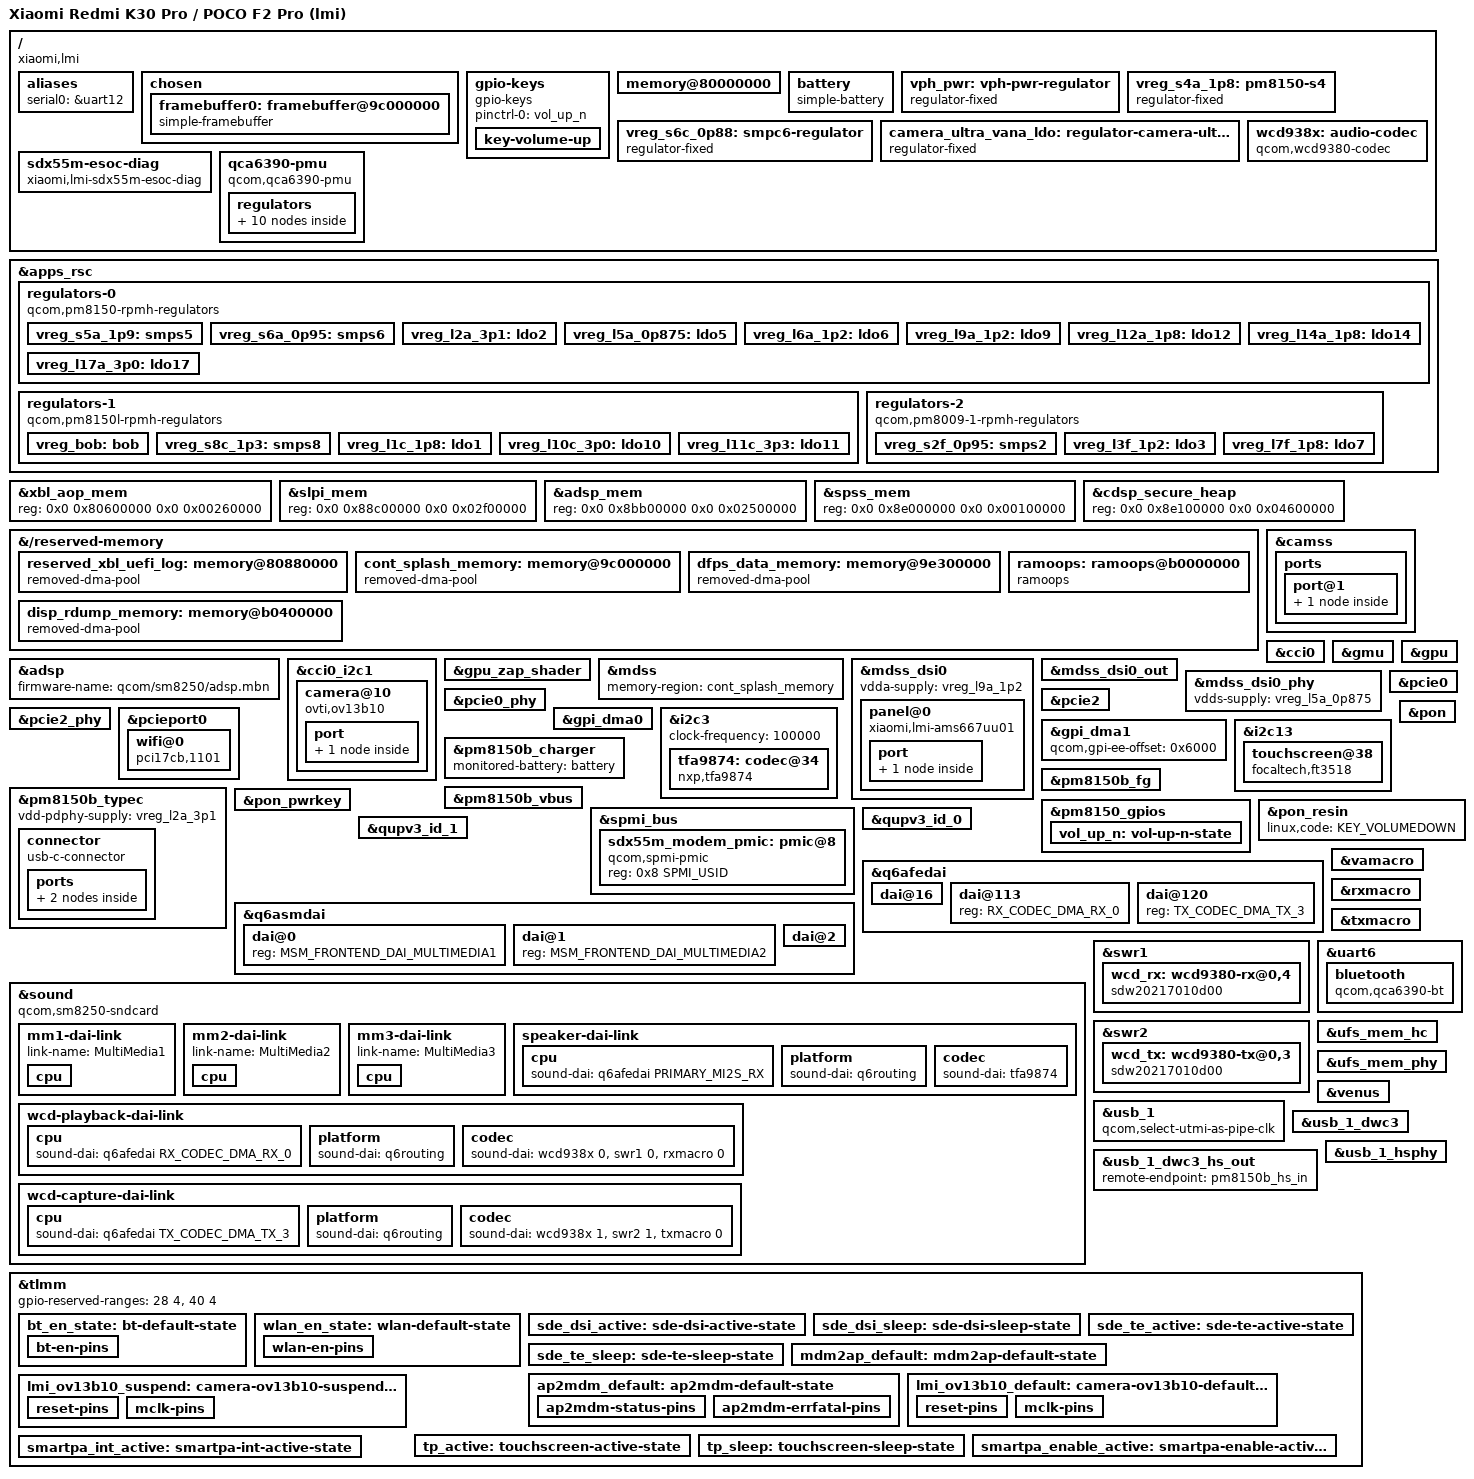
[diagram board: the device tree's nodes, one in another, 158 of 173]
/dts-v1/;

#include <dt-bindings/regulator/qcom,rpmh-regulator.h>
#include <dt-bindings/sound/qcom,q6afe.h>
#include <dt-bindings/sound/qcom,q6asm.h>
#include <dt-bindings/usb/pd.h>
#include "sm8250.dtsi"
#include "pm8150.dtsi"
#include "pm8150b.dtsi"

/ {
	model = "Xiaomi Redmi K30 Pro / POCO F2 Pro (lmi)";
	compatible = "xiaomi,lmi", "qcom,sm8250", "qcom,kona-mtp", "qcom,kona", "qcom,mtp";
	qcom,msm-id = <0x164 0x20001>;
	qcom,board-id = <0x25 0x00>;

	#address-cells = <2>;
	#size-cells = <2>;

	aliases {
		serial0 = &uart12;
	};

	chosen {
		#address-cells = <2>;
		#size-cells = <2>;
		ranges;

		stdout-path = "serial0:115200n8";
		bootargs = "clk_ignore_unused pd_ignore_unused fw_devlink=off pstore.backend=ramoops androidboot.hardware=qcom earlycon=msm_geni_serial,0xa90000 console=tty0 consoleblank=0 systemd.mask=serial-getty@ttyGS0.service loglevel=4 kpti=off loop.max_part=7 lpm_levels.sleep_disabled=1 reboot=panic_warm swiotlb=2048 cgroup.memory=nokmem,nosocket msm_rtb.filter=0x237 service_locator.enable=1 drm_client_lib.active=fbdev fbcon=font:TER16x32";

		framebuffer0: framebuffer@9c000000 {
			compatible = "simple-framebuffer";
			reg = <0x0 0x9c000000 0x0 0x02300000>;
			width = <1080>;
			height = <2400>;
			stride = <4352>;
			format = "a8r8g8b8";
			status = "okay";
		};
	};

	gpio-keys {
		compatible = "gpio-keys";

		pinctrl-0 = <&vol_up_n>;
		pinctrl-names = "default";

		key-volume-up {
			label = "Volume Up";
			gpios = <&pm8150_gpios 6 GPIO_ACTIVE_LOW>;
			linux,code = <KEY_VOLUMEUP>;
			debounce-interval = <15>;
			linux,can-disable;
			wakeup-source;
		};
	};

	memory@80000000 {
		device_type = "memory";
		reg = <0x0 0x80000000 0x0 0x3bb00000>,
		      <0x0 0xc0000000 0x0 0xc0000000>,
		      <0x1 0x80000000 0x1 0x00000000>;
	};

	battery: battery {
		compatible = "simple-battery";
		charge-full-design-microamp-hours = <4700000>;
		energy-full-design-microwatt-hours = <17500000>;
		voltage-min-design-microvolt = <3400000>;
		voltage-max-design-microvolt = <4460000>;
	};

	vph_pwr: vph-pwr-regulator {
		compatible = "regulator-fixed";
		regulator-name = "vph_pwr";
		regulator-min-microvolt = <3700000>;
		regulator-max-microvolt = <3700000>;
	};

	vreg_s4a_1p8: pm8150-s4 {
		compatible = "regulator-fixed";
		regulator-name = "vreg_s4a_1p8";
		regulator-min-microvolt = <1800000>;
		regulator-max-microvolt = <1800000>;
		regulator-always-on;
		regulator-boot-on;
		vin-supply = <&vph_pwr>;
	};

	vreg_s6c_0p88: smpc6-regulator {
		compatible = "regulator-fixed";
		regulator-name = "vreg_s6c_0p88";
		regulator-min-microvolt = <880000>;
		regulator-max-microvolt = <880000>;
		regulator-always-on;
		vin-supply = <&vph_pwr>;
	};

	camera_ultra_vana_ldo: regulator-camera-ultra-vana {
		compatible = "regulator-fixed";
		regulator-name = "camera_ultra_vana_ldo";
		regulator-min-microvolt = <2800000>;
		regulator-max-microvolt = <2800000>;
		gpio = <&tlmm 63 GPIO_ACTIVE_HIGH>;
		enable-active-high;
		startup-delay-us = <135>;
		vin-supply = <&vreg_bob>;
	};

	wcd938x: audio-codec {
		compatible = "qcom,wcd9380-codec";

		reset-gpios = <&tlmm 32 GPIO_ACTIVE_LOW>;

		vdd-buck-supply = <&vreg_s4a_1p8>;
		vdd-rxtx-supply = <&vreg_s4a_1p8>;
		vdd-io-supply = <&vreg_s4a_1p8>;
		vdd-mic-bias-supply = <&vreg_bob>;

		qcom,micbias1-microvolt = <2750000>;
		qcom,micbias2-microvolt = <2750000>;
		qcom,micbias3-microvolt = <2750000>;
		qcom,micbias4-microvolt = <2750000>;
		qcom,mbhc-buttons-vthreshold-microvolt = <75000 150000 237000 500000 500000 500000 500000 500000>;
		qcom,mbhc-headset-vthreshold-microvolt = <1700000>;
		qcom,mbhc-headphone-vthreshold-microvolt = <50000>;
		qcom,rx-device = <&wcd_rx>;
		qcom,tx-device = <&wcd_tx>;

		#sound-dai-cells = <1>;
	};

	sdx55m-esoc-diag {
		compatible = "xiaomi,lmi-sdx55m-esoc-diag";
		modem-pmic = <&sdx55m_modem_pmic>;
		modem-pon-base = <0x800>;
		ap2mdm-status-gpios = <&tlmm 56 GPIO_ACTIVE_HIGH>;
		ap2mdm-errfatal-gpios = <&tlmm 57 GPIO_ACTIVE_HIGH>;
		mdm2ap-status-gpios = <&tlmm 3 GPIO_ACTIVE_HIGH>;
		mdm2ap-errfatal-gpios = <&tlmm 1 GPIO_ACTIVE_HIGH>;
	};

	qca6390-pmu {
		compatible = "qcom,qca6390-pmu";

		pinctrl-names = "default";
		pinctrl-0 = <&bt_en_state>, <&wlan_en_state>;

		vddaon-supply = <&vreg_s6a_0p95>;
		vddpmu-supply = <&vreg_s2f_0p95>;
		vddrfa0p95-supply = <&vreg_s2f_0p95>;
		vddrfa1p3-supply = <&vreg_s8c_1p3>;
		vddrfa1p9-supply = <&vreg_s5a_1p9>;
		vddpcie1p3-supply = <&vreg_s8c_1p3>;
		vddpcie1p9-supply = <&vreg_s5a_1p9>;
		vddio-supply = <&vreg_s4a_1p8>;

		wlan-enable-gpios = <&tlmm 20 GPIO_ACTIVE_HIGH>;
		bt-enable-gpios = <&tlmm 21 GPIO_ACTIVE_HIGH>;

		regulators {
			vreg_pmu_rfa_cmn: ldo0 {
				regulator-name = "vreg_pmu_rfa_cmn";
			};

			vreg_pmu_aon_0p59: ldo1 {
				regulator-name = "vreg_pmu_aon_0p59";
			};

			vreg_pmu_wlcx_0p8: ldo2 {
				regulator-name = "vreg_pmu_wlcx_0p8";
			};

			vreg_pmu_wlmx_0p85: ldo3 {
				regulator-name = "vreg_pmu_wlmx_0p85";
			};

			vreg_pmu_btcmx_0p85: ldo4 {
				regulator-name = "vreg_pmu_btcmx_0p85";
			};

			vreg_pmu_rfa_0p8: ldo5 {
				regulator-name = "vreg_pmu_rfa_0p8";
			};

			vreg_pmu_rfa_1p2: ldo6 {
				regulator-name = "vreg_pmu_rfa_1p2";
			};

			vreg_pmu_rfa_1p7: ldo7 {
				regulator-name = "vreg_pmu_rfa_1p7";
			};

			vreg_pmu_pcie_0p9: ldo8 {
				regulator-name = "vreg_pmu_pcie_0p9";
			};

			vreg_pmu_pcie_1p8: ldo9 {
				regulator-name = "vreg_pmu_pcie_1p8";
			};
		};
	};

};

&apps_rsc {
	regulators-0 {
		compatible = "qcom,pm8150-rpmh-regulators";
		qcom,pmic-id = "a";

		vdd-s4-supply = <&vph_pwr>;
		vdd-s5-supply = <&vph_pwr>;
		vdd-s6-supply = <&vph_pwr>;
		vdd-l2-l10-supply = <&vreg_bob>;
		vdd-l3-l4-l5-l18-supply = <&vreg_s6a_0p95>;
		vdd-l6-l9-supply = <&vreg_s8c_1p3>;
		vdd-l7-l12-l14-l15-supply = <&vreg_s5a_1p9>;
		vdd-l13-l16-l17-supply = <&vreg_bob>;

		vreg_s5a_1p9: smps5 {
			regulator-name = "vreg_s5a_1p9";
			regulator-min-microvolt = <1904000>;
			regulator-max-microvolt = <2000000>;
			regulator-initial-mode = <RPMH_REGULATOR_MODE_HPM>;
		};

		vreg_s6a_0p95: smps6 {
			regulator-name = "vreg_s6a_0p95";
			regulator-min-microvolt = <920000>;
			regulator-max-microvolt = <1128000>;
			regulator-initial-mode = <RPMH_REGULATOR_MODE_HPM>;
		};

		vreg_l2a_3p1: ldo2 {
			regulator-name = "vreg_l2a_3p1";
			regulator-min-microvolt = <3072000>;
			regulator-max-microvolt = <3072000>;
			regulator-initial-mode = <RPMH_REGULATOR_MODE_HPM>;
		};

		vreg_l5a_0p875: ldo5 {
			regulator-name = "vreg_l5a_0p875";
			regulator-min-microvolt = <880000>;
			regulator-max-microvolt = <880000>;
			regulator-initial-mode = <RPMH_REGULATOR_MODE_HPM>;
		};

		vreg_l6a_1p2: ldo6 {
			regulator-name = "vreg_l6a_1p2";
			regulator-min-microvolt = <1200000>;
			regulator-max-microvolt = <1200000>;
			regulator-initial-mode = <RPMH_REGULATOR_MODE_HPM>;
			regulator-allow-set-load;
			regulator-allowed-modes = <RPMH_REGULATOR_MODE_LPM
						   RPMH_REGULATOR_MODE_HPM>;
		};

		vreg_l9a_1p2: ldo9 {
			regulator-name = "vreg_l9a_1p2";
			regulator-min-microvolt = <1200000>;
			regulator-max-microvolt = <1200000>;
			regulator-initial-mode = <RPMH_REGULATOR_MODE_HPM>;
		};

		vreg_l12a_1p8: ldo12 {
			regulator-name = "vreg_l12a_1p8";
			regulator-min-microvolt = <1800000>;
			regulator-max-microvolt = <1800000>;
			regulator-initial-mode = <RPMH_REGULATOR_MODE_HPM>;
		};

		vreg_l14a_1p8: ldo14 {
			regulator-name = "vreg_l14a_1p8";
			regulator-min-microvolt = <1800000>;
			regulator-max-microvolt = <1880000>;
			regulator-initial-mode = <RPMH_REGULATOR_MODE_HPM>;
		};

		vreg_l17a_3p0: ldo17 {
			regulator-name = "vreg_l17a_3p0";
			regulator-min-microvolt = <2856000>;
			regulator-max-microvolt = <3008000>;
			regulator-initial-mode = <RPMH_REGULATOR_MODE_HPM>;
			regulator-allow-set-load;
			regulator-allowed-modes = <RPMH_REGULATOR_MODE_LPM
						   RPMH_REGULATOR_MODE_HPM>;
		};
	};

	regulators-1 {
		compatible = "qcom,pm8150l-rpmh-regulators";
		qcom,pmic-id = "c";

		vdd-s8-supply = <&vph_pwr>;
		vdd-l1-l8-supply = <&vreg_s4a_1p8>;
		vdd-l7-l11-supply = <&vreg_bob>;
		vdd-l9-l10-supply = <&vreg_bob>;
		vdd-bob-supply = <&vph_pwr>;

		vreg_bob: bob {
			regulator-name = "vreg_bob";
			regulator-min-microvolt = <3008000>;
			regulator-max-microvolt = <4000000>;
			regulator-initial-mode = <RPMH_REGULATOR_MODE_AUTO>;
		};

		vreg_s8c_1p3: smps8 {
			regulator-name = "vreg_s8c_1p3";
			regulator-min-microvolt = <1352000>;
			regulator-max-microvolt = <1352000>;
			regulator-initial-mode = <RPMH_REGULATOR_MODE_HPM>;
		};

		vreg_l1c_1p8: ldo1 {
			regulator-name = "vreg_l1c_1p8";
			regulator-min-microvolt = <1800000>;
			regulator-max-microvolt = <1800000>;
			regulator-initial-mode = <RPMH_REGULATOR_MODE_HPM>;
		};

		vreg_l10c_3p0: ldo10 {
			regulator-name = "vreg_l10c_3p0";
			regulator-min-microvolt = <3000000>;
			regulator-max-microvolt = <3000000>;
			regulator-initial-mode = <RPMH_REGULATOR_MODE_HPM>;
		};

		vreg_l11c_3p3: ldo11 {
			regulator-name = "vreg_l11c_3p3";
			regulator-min-microvolt = <3000000>;
			regulator-max-microvolt = <3312000>;
			regulator-initial-mode = <RPMH_REGULATOR_MODE_HPM>;
		};
	};

	regulators-2 {
		compatible = "qcom,pm8009-1-rpmh-regulators";
		qcom,pmic-id = "f";

		vdd-s1-supply = <&vph_pwr>;
		vdd-s2-supply = <&vph_pwr>;
		vdd-l2-supply = <&vreg_s8c_1p3>;
		vdd-l3-l4-supply = <&vreg_bob>;
		vdd-l5-l6-supply = <&vreg_bob>;
		vdd-l7-supply = <&vreg_s4a_1p8>;

		vreg_s2f_0p95: smps2 {
			regulator-name = "vreg_s2f_0p95";
			regulator-min-microvolt = <900000>;
			regulator-max-microvolt = <952000>;
			regulator-initial-mode = <RPMH_REGULATOR_MODE_AUTO>;
		};

		vreg_l3f_1p2: ldo3 {
			regulator-name = "vreg_l3f_1p2";
			regulator-min-microvolt = <1200000>;
			regulator-max-microvolt = <1200000>;
			regulator-initial-mode = <RPMH_REGULATOR_MODE_HPM>;
			regulator-allow-set-load;
			regulator-allowed-modes = <RPMH_REGULATOR_MODE_LPM
						   RPMH_REGULATOR_MODE_HPM>;
		};

		vreg_l7f_1p8: ldo7 {
			regulator-name = "vreg_l7f_1p8";
			regulator-min-microvolt = <1800000>;
			regulator-max-microvolt = <1800000>;
			regulator-initial-mode = <RPMH_REGULATOR_MODE_HPM>;
			regulator-allow-set-load;
			regulator-allowed-modes = <RPMH_REGULATOR_MODE_LPM
						   RPMH_REGULATOR_MODE_HPM>;
		};
	};
};

&xbl_aop_mem {
	reg = <0x0 0x80600000 0x0 0x00260000>;
};

&slpi_mem {
	reg = <0x0 0x88c00000 0x0 0x02f00000>;
};

&adsp_mem {
	reg = <0x0 0x8bb00000 0x0 0x02500000>;
};

&spss_mem {
	reg = <0x0 0x8e000000 0x0 0x00100000>;
};

&cdsp_secure_heap {
	reg = <0x0 0x8e100000 0x0 0x04600000>;
};

&{/reserved-memory} {
	reserved_xbl_uefi_log: memory@80880000 {
		compatible = "removed-dma-pool";
		no-map;
		reg = <0x0 0x80880000 0x0 0x00014000>;
	};

	cont_splash_memory: memory@9c000000 {
		compatible = "removed-dma-pool";
		no-map;
		reg = <0x0 0x9c000000 0x0 0x02300000>;
		label = "cont_splash_region";
	};

	dfps_data_memory: memory@9e300000 {
		compatible = "removed-dma-pool";
		no-map;
		reg = <0x0 0x9e300000 0x0 0x00100000>;
		label = "dfps_data_region";
	};

	ramoops: ramoops@b0000000 {
		compatible = "ramoops";
		no-map;
		reg = <0x0 0xb0000000 0x0 0x00400000>;
		record-size = <0x0>;
		console-size = <0x00200000>;
		pmsg-size = <0x00200000>;
		ecc-size = <0x0>;
		max-reason = <3>;
	};

	disp_rdump_memory: memory@b0400000 {
		compatible = "removed-dma-pool";
		no-map;
		reg = <0x0 0xb0400000 0x0 0x01000000>;
		label = "disp_rdump_region";
	};
};

&adsp {
	firmware-name = "qcom/sm8250/adsp.mbn";
	status = "okay";
};

&camss {
	vdda-phy-supply = <&vreg_l5a_0p875>;
	vdda-pll-supply = <&vreg_l9a_1p2>;
	status = "okay";

	ports {
		port@1 {
			csiphy1_ep: endpoint {
				clock-lanes = <7>;
				data-lanes = <0 1 2 3>;
				remote-endpoint = <&ov13b10_ep>;
			};
		};
	};
};

&cci0 {
	status = "okay";
};

&cci0_i2c1 {
	camera@10 {
		compatible = "ovti,ov13b10";
		reg = <0x10>;

		clocks = <&camcc CAM_CC_MCLK2_CLK>;
		assigned-clocks = <&camcc CAM_CC_MCLK2_CLK>;
		assigned-clock-rates = <19200000>;
		orientation = <1>;
		rotation = <90>;

		reset-gpios = <&tlmm 91 GPIO_ACTIVE_LOW>;
		pinctrl-0 = <&lmi_ov13b10_default>;
		pinctrl-1 = <&lmi_ov13b10_suspend>;
		pinctrl-names = "default", "suspend";

		avdd-supply = <&camera_ultra_vana_ldo>;
		dovdd-supply = <&vreg_l7f_1p8>;
		dvdd-supply = <&vreg_l3f_1p2>;

		port {
			ov13b10_ep: endpoint {
				data-lanes = <1 2 3 4>;
				link-frequencies = /bits/ 64 <560000000>;
				remote-endpoint = <&csiphy1_ep>;
			};
		};
	};
};

&gmu {
	status = "okay";
};

&gpu {
	status = "okay";
};

&gpu_zap_shader {
	firmware-name = "qcom/sm8250/xiaomi/lmi/a650_zap.mdt";
};

&mdss {
	memory-region = <&cont_splash_memory>;
	status = "okay";
};

&mdss_dsi0 {
	vdda-supply = <&vreg_l9a_1p2>;
	status = "okay";

	panel@0 {
		compatible = "xiaomi,lmi-ams667uu01";
		reg = <0>;

		pinctrl-0 = <&sde_dsi_active>, <&sde_te_active>;
		pinctrl-1 = <&sde_dsi_sleep>, <&sde_te_sleep>;
		pinctrl-names = "default", "sleep";

		vddio-supply = <&vreg_l14a_1p8>;
		vci-supply = <&vreg_l10c_3p0>;
		reset-gpios = <&tlmm 46 GPIO_ACTIVE_LOW>;

		port {
			panel_in: endpoint {
				remote-endpoint = <&mdss_dsi0_out>;
			};
		};
	};
};

&mdss_dsi0_out {
	remote-endpoint = <&panel_in>;
	data-lanes = <0 1 2 3>;
};

&mdss_dsi0_phy {
	vdds-supply = <&vreg_l5a_0p875>;
	status = "okay";
};

&pcie0 {
	vdda-supply = <&vreg_l9a_1p2>;
	vddpe-3v3-supply = <&vreg_l11c_3p3>;
	status = "okay";
};

&pcie0_phy {
	vdda-phy-supply = <&vreg_s6c_0p88>;
	vdda-pll-supply = <&vreg_l9a_1p2>;
	status = "okay";
};

&pcie2 {
	pinctrl-0 = <&pcie2_default_state &mdm2ap_default &ap2mdm_default>;
	vdda-supply = <&vreg_l9a_1p2>;
	vddpe-3v3-supply = <&vreg_l11c_3p3>;
	status = "okay";
};

&pcie2_phy {
	vdda-phy-supply = <&vreg_l5a_0p875>;
	vdda-pll-supply = <&vreg_l9a_1p2>;
	status = "okay";
};

&pcieport0 {
	wifi@0 {
		compatible = "pci17cb,1101";
		reg = <0x10000 0x0 0x0 0x0 0x0>;

		vddrfacmn-supply = <&vreg_pmu_rfa_cmn>;
		vddaon-supply = <&vreg_pmu_aon_0p59>;
		vddwlcx-supply = <&vreg_pmu_wlcx_0p8>;
		vddwlmx-supply = <&vreg_pmu_wlmx_0p85>;
		vddrfa0p8-supply = <&vreg_pmu_rfa_0p8>;
		vddrfa1p2-supply = <&vreg_pmu_rfa_1p2>;
		vddrfa1p7-supply = <&vreg_pmu_rfa_1p7>;
		vddpcie0p9-supply = <&vreg_pmu_pcie_0p9>;
		vddpcie1p8-supply = <&vreg_pmu_pcie_1p8>;
	};
};

&gpi_dma0 {
	status = "okay";
};

&gpi_dma1 {
	qcom,gpi-ee-offset = <0x6000>;
	status = "okay";
};

&i2c3 {
	clock-frequency = <100000>;
	status = "okay";

	tfa9874: codec@34 {
		compatible = "nxp,tfa9874";
		reg = <0x34>;

		reset-gpios = <&tlmm 114 GPIO_ACTIVE_HIGH>;

		pinctrl-0 = <&smartpa_int_active &smartpa_enable_active>;
		pinctrl-names = "default";

		sound-name-prefix = "Speaker";
		#sound-dai-cells = <0>;
	};
};

&i2c13 {
	status = "okay";

	touchscreen@38 {
		compatible = "focaltech,ft3518";
		reg = <0x38>;
		interrupt-parent = <&tlmm>;
		interrupts = <39 IRQ_TYPE_EDGE_FALLING>;
		reset-gpios = <&tlmm 38 GPIO_ACTIVE_LOW>;

		pinctrl-0 = <&tp_active>;
		pinctrl-1 = <&tp_sleep>;
		pinctrl-names = "default", "sleep";

		touchscreen-size-x = <1080>;
		touchscreen-size-y = <2400>;

		vcc-supply = <&vreg_l10c_3p0>;
		iovcc-supply = <&vreg_l1c_1p8>;
	};
};

&pm8150b_typec {
	vdd-pdphy-supply = <&vreg_l2a_3p1>;
	status = "okay";

	connector {
		compatible = "usb-c-connector";
		op-sink-microwatt = <18000000>;
		power-role = "dual";
		data-role = "dual";
		self-powered;

		source-pdos = <PDO_FIXED(5000, 3000,
					 PDO_FIXED_DUAL_ROLE |
					 PDO_FIXED_USB_COMM |
					 PDO_FIXED_DATA_SWAP)>;
		sink-pdos = <PDO_FIXED(5000, 3000,
				       PDO_FIXED_DUAL_ROLE |
				       PDO_FIXED_USB_COMM |
				       PDO_FIXED_DATA_SWAP)
			     PDO_VAR(5000, 12000, 3000)>;

		ports {
			#address-cells = <1>;
			#size-cells = <0>;

			port@0 {
				reg = <0>;

				pm8150b_hs_in: endpoint {
					remote-endpoint = <&usb_1_dwc3_hs_out>;
				};
			};
		};
	};
};

&pm8150b_charger {
	status = "okay";
	monitored-battery = <&battery>;
};

&pm8150b_fg {
	status = "okay";
	monitored-battery = <&battery>;
	power-supplies = <&pm8150b_charger>;
};

&pm8150b_vbus {
	regulator-min-microamp = <500000>;
	regulator-max-microamp = <3000000>;
	status = "okay";
};

&pm8150_gpios {
	vol_up_n: vol-up-n-state {
		pins = "gpio6";
		function = "normal";
		power-source = <1>;
		input-enable;
		bias-pull-up;
	};
};

&pon {
	mode-bootloader = <0x2>;
	mode-fastboot = <0x2>;
	mode-recovery = <0x1>;
};

&pon_pwrkey {
	status = "okay";
};

&pon_resin {
	linux,code = <KEY_VOLUMEDOWN>;
	status = "okay";
};

&spmi_bus {
	sdx55m_modem_pmic: pmic@8 {
		compatible = "qcom,spmi-pmic";
		reg = <0x8 SPMI_USID>;
		#address-cells = <1>;
		#size-cells = <0>;
	};
};

&qupv3_id_0 {
	status = "okay";
};

&qupv3_id_1 {
	status = "okay";
};

&q6afedai {
	dai@16 {
		reg = <PRIMARY_MI2S_RX>;
		qcom,sd-lines = <0>;
	};

	dai@113 {
		reg = <RX_CODEC_DMA_RX_0>;
	};

	dai@120 {
		reg = <TX_CODEC_DMA_TX_3>;
	};
};

&q6asmdai {
	dai@0 {
		reg = <MSM_FRONTEND_DAI_MULTIMEDIA1>;
	};

	dai@1 {
		reg = <MSM_FRONTEND_DAI_MULTIMEDIA2>;
	};

	dai@2 {
		reg = <MSM_FRONTEND_DAI_MULTIMEDIA3>;
		is-compress-dai;
	};
};

&sound {
	compatible = "qcom,sm8250-sndcard";
	pinctrl-0 = <&pri_mi2s_active>;
	pinctrl-names = "default";
	model = "Xiaomi lmi";
	audio-routing =
		"IN1_HPHL", "HPHL_OUT",
		"IN2_HPHR", "HPHR_OUT",
		"IN3_AUX", "AUX_OUT",
		"AMIC1", "MIC BIAS1",
		"AMIC2", "MIC BIAS2",
		"AMIC3", "MIC BIAS3",
		"AMIC4", "MIC BIAS3",
		"AMIC5", "MIC BIAS4",
		"ADC1", "AMIC1",
		"ADC2", "AMIC2",
		"ADC3", "AMIC3",
		"ADC4", "AMIC4",
		"TX SWR_ADC0", "ADC1_OUTPUT",
		"TX SWR_ADC1", "ADC2_OUTPUT",
		"TX SWR_ADC2", "ADC3_OUTPUT",
		"TX SWR_ADC3", "ADC4_OUTPUT",
		"RX_TX DEC0_INP", "TX DEC0 MUX",
		"RX_TX DEC1_INP", "TX DEC1 MUX",
		"RX_TX DEC2_INP", "TX DEC2 MUX",
		"RX_TX DEC3_INP", "TX DEC3 MUX";

	mm1-dai-link {
		link-name = "MultiMedia1";

		cpu {
			sound-dai = <&q6asmdai MSM_FRONTEND_DAI_MULTIMEDIA1>;
		};
	};

	mm2-dai-link {
		link-name = "MultiMedia2";

		cpu {
			sound-dai = <&q6asmdai MSM_FRONTEND_DAI_MULTIMEDIA2>;
		};
	};

	mm3-dai-link {
		link-name = "MultiMedia3";

		cpu {
			sound-dai = <&q6asmdai MSM_FRONTEND_DAI_MULTIMEDIA3>;
		};
	};

	speaker-dai-link {
		link-name = "TFA9874 Playback";
		no-pcm;

		cpu {
			sound-dai = <&q6afedai PRIMARY_MI2S_RX>;
		};

		platform {
			sound-dai = <&q6routing>;
		};

		codec {
			sound-dai = <&tfa9874>;
		};
	};

	wcd-playback-dai-link {
		link-name = "WCD Playback";
		no-pcm;

		cpu {
			sound-dai = <&q6afedai RX_CODEC_DMA_RX_0>;
		};

		platform {
			sound-dai = <&q6routing>;
		};

		codec {
			sound-dai = <&wcd938x 0>, <&swr1 0>, <&rxmacro 0>;
		};
	};

	wcd-capture-dai-link {
		link-name = "WCD Capture";
		no-pcm;

		cpu {
			sound-dai = <&q6afedai TX_CODEC_DMA_TX_3>;
		};

		platform {
			sound-dai = <&q6routing>;
		};

		codec {
			sound-dai = <&wcd938x 1>, <&swr2 1>, <&txmacro 0>;
		};
	};
};

&vamacro {
	vdd-micb-supply = <&vreg_bob>;
	qcom,dmic-sample-rate = <4800000>;
	status = "okay";
};

&rxmacro {
	status = "okay";
};

&txmacro {
	status = "okay";
};

&swr1 {
	status = "okay";

	wcd_rx: wcd9380-rx@0,4 {
		compatible = "sdw20217010d00";
		reg = <0 4>;
		qcom,rx-port-mapping = <1 2 3 4 5>;
	};
};

&swr2 {
	status = "okay";

	wcd_tx: wcd9380-tx@0,3 {
		compatible = "sdw20217010d00";
		reg = <0 3>;
		qcom,tx-port-mapping = <2 3 4 5>;
	};
};

&uart6 {
	status = "okay";

	bluetooth {
		compatible = "qcom,qca6390-bt";
		vddrfacmn-supply = <&vreg_pmu_rfa_cmn>;
		vddaon-supply = <&vreg_pmu_aon_0p59>;
		vddbtcmx-supply = <&vreg_pmu_btcmx_0p85>;
		vddrfa0p8-supply = <&vreg_pmu_rfa_0p8>;
		vddrfa1p2-supply = <&vreg_pmu_rfa_1p2>;
		vddrfa1p7-supply = <&vreg_pmu_rfa_1p7>;
	};
};

&ufs_mem_hc {
	vcc-supply = <&vreg_l17a_3p0>;
	vcc-max-microamp = <800000>;
	vccq-supply = <&vreg_l6a_1p2>;
	vccq-max-microamp = <800000>;
	vccq2-supply = <&vreg_s4a_1p8>;
	vccq2-max-microamp = <800000>;
	status = "okay";
};

&ufs_mem_phy {
	vdda-phy-supply = <&vreg_l5a_0p875>;
	vdda-pll-supply = <&vreg_l9a_1p2>;
	status = "okay";
};

&venus {
	firmware-name = "qcom/sm8250/xiaomi/lmi/venus.mbn";
	status = "okay";
};

&usb_1 {
	qcom,select-utmi-as-pipe-clk;
	status = "okay";
};

&usb_1_dwc3 {
	dr_mode = "otg";
	maximum-speed = "high-speed";
	phys = <&usb_1_hsphy>;
	phy-names = "usb2-phy";
	usb-role-switch;
};

&usb_1_dwc3_hs_out {
	remote-endpoint = <&pm8150b_hs_in>;
};

&usb_1_hsphy {
	vdda-pll-supply = <&vreg_l5a_0p875>;
	vdda18-supply = <&vreg_l12a_1p8>;
	vdda33-supply = <&vreg_l2a_3p1>;
	status = "okay";
};

&tlmm {
	status = "okay";
	gpio-reserved-ranges = <28 4>, <40 4>;

	bt_en_state: bt-default-state {
		bt-en-pins {
			pins = "gpio21";
			function = "gpio";
			drive-strength = <16>;
			output-low;
			bias-pull-up;
		};
	};

	wlan_en_state: wlan-default-state {
		wlan-en-pins {
			pins = "gpio20";
			function = "gpio";
			drive-strength = <16>;
			output-low;
			bias-pull-up;
		};
	};

	sde_dsi_active: sde-dsi-active-state {
		pins = "gpio46";
		function = "gpio";
		drive-strength = <8>;
		bias-disable;
		output-high;
	};

	sde_dsi_sleep: sde-dsi-sleep-state {
		pins = "gpio46";
		function = "gpio";
		drive-strength = <2>;
		bias-pull-down;
		output-high;
	};

	sde_te_active: sde-te-active-state {
		pins = "gpio66";
		function = "mdp_vsync";
		drive-strength = <2>;
		bias-pull-down;
	};

	sde_te_sleep: sde-te-sleep-state {
		pins = "gpio66";
		function = "mdp_vsync";
		drive-strength = <2>;
		bias-pull-down;
	};

	mdm2ap_default: mdm2ap-default-state {
		pins = "gpio1", "gpio3";
		function = "gpio";
		drive-strength = <8>;
		bias-disable;
	};

	ap2mdm_default: ap2mdm-default-state {
		ap2mdm-status-pins {
			pins = "gpio56";
			function = "gpio";
			drive-strength = <16>;
			output-low;
			bias-disable;
		};

		ap2mdm-errfatal-pins {
			pins = "gpio57";
			function = "gpio";
			drive-strength = <16>;
			output-low;
			bias-disable;
		};
	};

	lmi_ov13b10_default: camera-ov13b10-default-state {
		reset-pins {
			pins = "gpio91";
			function = "gpio";
			drive-strength = <2>;
			bias-disable;
		};

		mclk-pins {
			pins = "gpio96";
			function = "cam_mclk";
			drive-strength = <4>;
			bias-disable;
		};
	};

	lmi_ov13b10_suspend: camera-ov13b10-suspend-state {
		reset-pins {
			pins = "gpio91";
			function = "gpio";
			drive-strength = <2>;
			bias-pull-down;
			output-low;
		};

		mclk-pins {
			pins = "gpio96";
			function = "cam_mclk";
			drive-strength = <4>;
			bias-pull-down;
		};
	};

	tp_active: touchscreen-active-state {
		pins = "gpio38", "gpio39", "gpio72";
		function = "gpio";
		drive-strength = <16>;
		bias-pull-up;
	};

	tp_sleep: touchscreen-sleep-state {
		pins = "gpio38", "gpio39";
		function = "gpio";
		drive-strength = <2>;
		bias-pull-up;
	};

	smartpa_enable_active: smartpa-enable-active-state {
		pins = "gpio114";
		function = "gpio";
		drive-strength = <2>;
		bias-pull-down;
		output-low;
	};

	smartpa_int_active: smartpa-int-active-state {
		pins = "gpio100";
		function = "gpio";
		drive-strength = <2>;
		bias-pull-up;
		input-enable;
	};
};
